# iVLCD register map
Vendor: Texas Instruments
Peripheral module from a debugger description file (folder omap36xx).
Registers are 32-bit, read-write, reset 0x0 unless marked. A register's access mark holds for its fields unless they carry their own. Offsets are as the file gives them; lines under a group give offsets from that group; [hi:lo] are bit positions; {n}, {i} and the like mark numbered series; 'fields as' and 'values as' point back to an identical list; <NAME> marks a mode.

## iVLCD
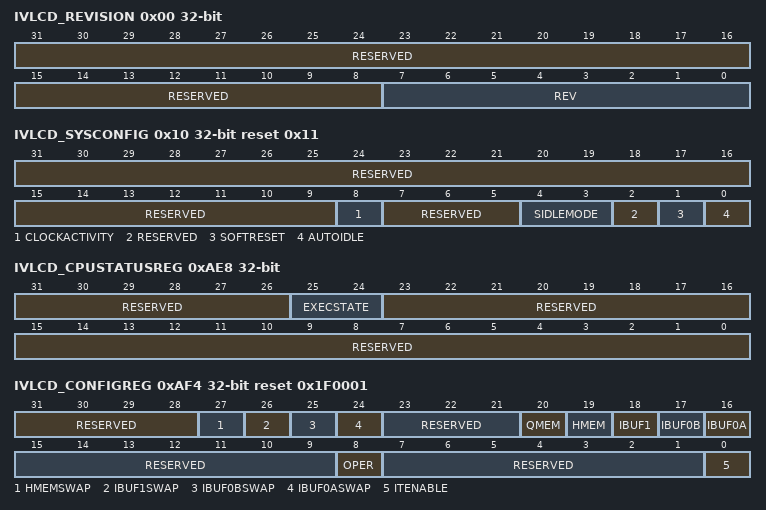
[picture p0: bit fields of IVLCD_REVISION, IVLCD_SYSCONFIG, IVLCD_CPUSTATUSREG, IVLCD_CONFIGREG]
0x00 IVLCD_REVISION ro (reset mask 0xFFFFFF00) — This register contains the iVLCD revision code
  [31:8] RESERVED — Reads return 0
  [7:0] REV — iVLCD Revision[3:0] Minor Revision[7:4] Major Revision
0x10 IVLCD_SYSCONFIG access per field reset 0x11 — This register allows controlling various parameters of the OCP interface
  [31:9] RESERVED rw — Read returns 0.Write has no effect (write a 0 for forward compatibility)
  [8] CLOCKACTIVITY ro — Clock activity during wake up mode period. 0 - OCP clock can be switched-off.
  [7:5] RESERVED rw — Read returns 0.Write has no effect (write a 0 for forward compatibility)
  [4:3] SIDLEMODE ro — Slave interface power management, req/ack control '10' = Smart-idle. Acknowledgement to an idle request is given based on the internal activity of iME
  [2] RESERVED rw — read returns 0.write has no effect (write a 0 for forward compatibility)
  [1] SOFTRESET rw — Software reset. Set this bit to 1 to trigger the iME reset.The bit is automatically reset by the hardware. During reads, it always returns 0.
  [0] AUTOIDLE rw — Internal OCP clock gating strategy: 0: OCP clock is free running 1: Automatic OCP clock-gating strategy is applied based on the OCP interface activity
0x14 IVLCD_SYSSTATUS ro reset 0x1 — The register provides status information about the module, excluding the interrupt information.
  [0] RESETDONE — Internal reset monitoring 0 Internal module reset is on-going 1 Reset completed
0xAE8 IVLCD_CPUSTATUSREG ro — CPU Status Register provides information about the progress of the CPU execution
  [31:26] RESERVED — Read returns 0.
  [25:24] EXECSTATE — Execution States:00 = Initialized,10 = Executing,01 = Halted,11 = Completed.
  [23:0] RESERVED — Read returns 0.
0xAF4 IVLCD_CONFIGREG access per field reset 0x1F0001 — Configuration Register
  [31:28] RESERVED ro — read returns 0.
  [27] HMEMSWAP rw — Enable 2 byte swap for host OCP access to this memory. Bytes 0.1.2.3 are swapped to 1.0.3.2 for both reads and writes.0 - Disabled (Native order)1 - Swapped
  [26] IBUF1SWAP rw — Enable 4 byte swap for host OCP access to this memory. Bytes 0.1.2.3 are swapped to 3.2.1.0 for both reads and writes.0 - Disabled (Native order)1 - Swapped
  [25] IBUF0BSWAP rw — IBUF0B 4 byte swap enable
  [24] IBUF0ASWAP rw — IBUF0A 4 byte swap enable
  [23:21] RESERVED ro — read returns 0.
  [20] QMEM rw — QMEM ownership: 0: QMEM is owned by xVLCD1: QMEM is owned by HOST
  [19] HMEM rw — HMEM ownership: 0: HMEM is owned by xVLCD1: HMEM is owned by HOST
  [18] IBUF1 rw — IBUF1 ownership: 0: IBFU1 is owned by xVLCD1: IBFU1 is owned by HOST
  [17] IBUF0B rw — IBUF0B ownership: 0: IBFU0B is owned by xVLCD1: IBFU0B is owned by HOST
  [16] IBUF0A rw — IBUF0A ownership: 0: IBFU0A is owned by xVLCD1: IBFU0A is owned by HOST
  [15:9] RESERVED ro — read returns 0.
  [8] OPER rw — Operation Type: Used to identify which start to issue to the xVLCD when a START command is set to the iVLCD.0 - VLCD1 - CAVLC
  [7:1] RESERVED ro — Read returns 0.
  [0] ITENABLE rw — Interrupt Enable bit. Controls interrupt regardless of VLCD or CAVLC operation.
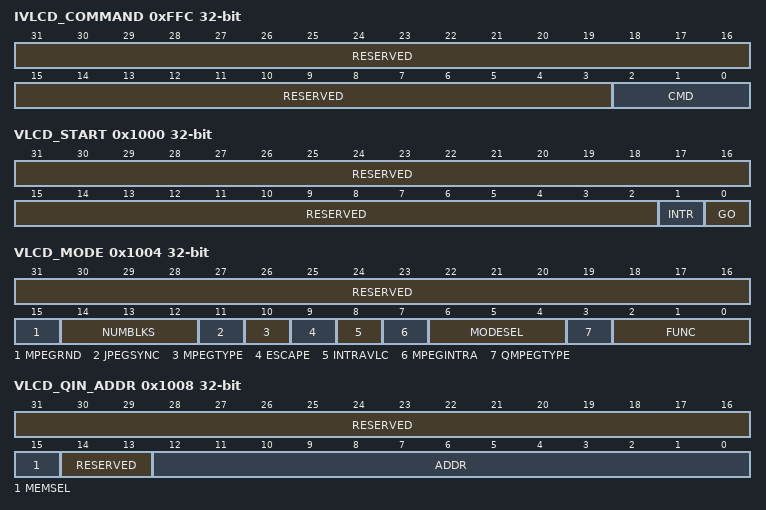
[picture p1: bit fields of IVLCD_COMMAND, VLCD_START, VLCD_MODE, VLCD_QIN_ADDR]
0xFFC IVLCD_COMMAND — Initiate iVLCD operations
  [31:3] RESERVED — Write 0s for future compatibilityRead returns 0
  [2:0] CMD — Triggers iVLCD operations Reads of this register return the last command that was issued to the iVLCD
    1=Start sequence; 2=Stop sequence; 3=Debug enable; 4=Debug disable; 5=Debug Step; 6=Debug Halt
0x1000 VLCD_START — This register starts the VLCD and enables or disables the VLCD interrupt.
  [31:2] RESERVED — Write 0s for future compatibilityRead returns 0
  [1] INTR — Interrupt enable 0: Interrupt is disabled1: Interrupt is enabled
  [0] GO — VLCD startRead0: VLCD idle1: VLCD busy.
0x1004 VLCD_MODE (reset mask 0xFFFFFFF8) — This register sets the VLCD modes.
  [31:16] RESERVED — Write 0s for future compatibilityRead returns 0
  [15] MPEGRND — Round control for the MPEG inverse quantization0: Round off1: Round on
  [14:12] NUMBLKS — Sets the number of blocksRange from 1 '001' to 6 '110'
  [11] JPEGSYNC — Sets the JPEG Sync Insertion0: Off1: On. Inserts 0x00 after 0xFF.
  [10] MPEGTYPE — Sets the MPEG picture coding type0: I, P, B picture1: D picture
  [9] ESCAPE — MPEG4 escape encoding0: Escape3 only1: Escape 1, 2 and 3
  [8] INTRAVLC — MPEG intra VLC format
  [7] MPEGINTRA — Sets the macro block (MB) type0: Non intra macro block1: Intra macro block (JPEG uses only intra MB).
  [6:4] MODESEL — Sets the CODEC type for the VLCD operations000: JPEG001: MPEG1010: MPEG4011: H.263100 - 111: ReservedSee also[5:4] MPGMOD and [2] MP2ENCDEC .
  [3] QMPEGTYPE — Sets the quantization type use for encode and decode.Used in MPEG4.
  [2:0] FUNC — Defines functionality of VLCD
    0=Q; 1=IQ; 2=VLC; 3=VLD; 4=Q + IQ; 5=Q+VLC; 6=Q+IQ+VLC; 7=VLD+IQ
0x1008 VLCD_QIN_ADDR — This register sets the input address for the quantization computation.
  [31:16] RESERVED — Write 0s for future compatibilityRead returns 0
  [15] MEMSEL — Sets the buffer used for the computation0: IMG BUF A/B1: IMG BUF1
  [14:13] RESERVED — Write 0s for future compatibilityRead returns 0
  [12:0] ADDR — Sets the start address for the computation
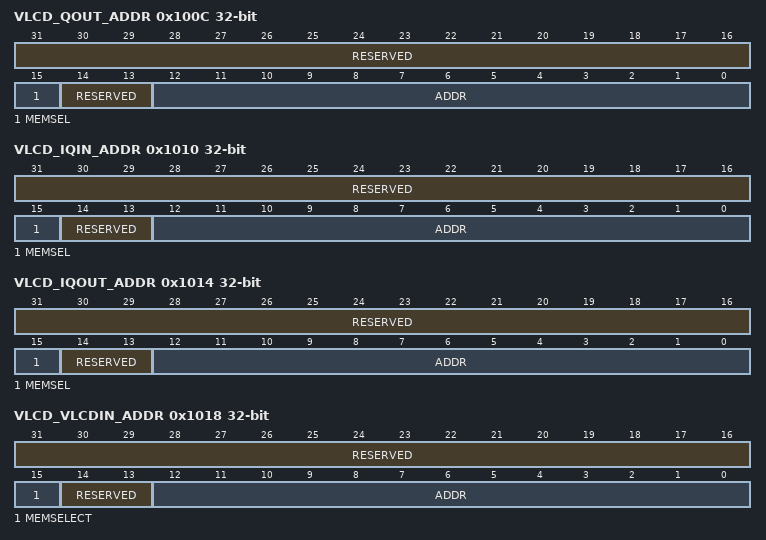
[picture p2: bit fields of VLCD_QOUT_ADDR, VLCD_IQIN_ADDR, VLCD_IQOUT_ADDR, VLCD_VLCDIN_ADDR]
0x100C VLCD_QOUT_ADDR — This register sets the output address for the quantization computation.
  fields as VLCD_QIN_ADDR
0x1010 VLCD_IQIN_ADDR — This register sets the input address for the inverse quantization computation.
  fields as VLCD_QIN_ADDR
0x1014 VLCD_IQOUT_ADDR — This register sets the output address for the inverse quantization output address.
  fields as VLCD_QIN_ADDR
0x1018 VLCD_VLCDIN_ADDR — This register sets the input address for the variable length coder and decoder operations.
  [31:16] RESERVED — Write 0s for future compatibilityRead returns 0
  [15] MEMSELECT — Sets the buffer used for the computation0: IMG BUF A/B1: IMG BUF1
  [14:13] RESERVED — Write 0s for future compatibilityRead returns 0
  [12:0] ADDR — Sets the start address for the computation
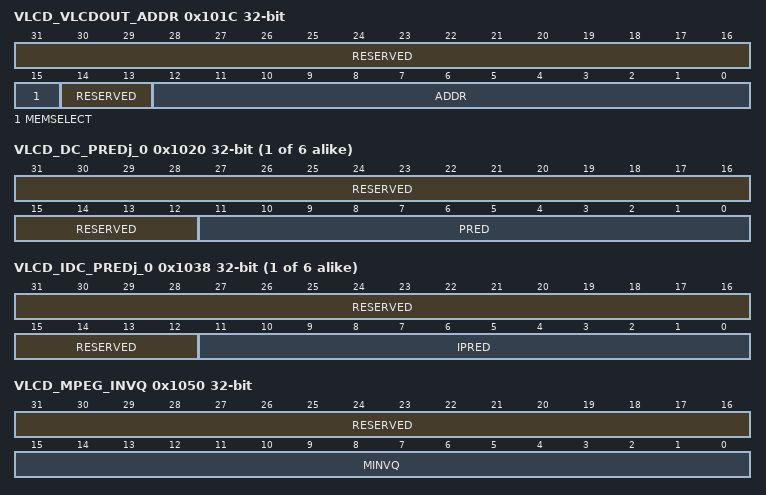
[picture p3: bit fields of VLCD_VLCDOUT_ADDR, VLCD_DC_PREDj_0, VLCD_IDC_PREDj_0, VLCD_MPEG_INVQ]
0x101C VLCD_VLCDOUT_ADDR — This register sets the output address for the variable length coder and decoder operations.
  fields as VLCD_VLCDIN_ADDR
{0x1020+4i} VLCD_DC_PREDj_{i} (i=0..5) — This register sets the initial/final DC predictors for Quantization
  [31:12] RESERVED — Write 0s for future compatibilityRead returns 0
  [11:0] PRED — Initial/ final DC predictor value
{0x1038+4i} VLCD_IDC_PREDj_{i} (i=0..5) — This register sets the initial/final DC predictors for Inverse Quantization
  [31:12] RESERVED — Write 0s for future compatibilityRead returns 0
  [11:0] IPRED — Initial/ final DC predictor value
0x1050 VLCD_MPEG_INVQ — This register sets the inverse quantization value used in MPEG.
  [31:16] RESERVED — Write 0s for future compatibilityRead returns 0
  [15:0] MINVQ — 2^15/quant_scale
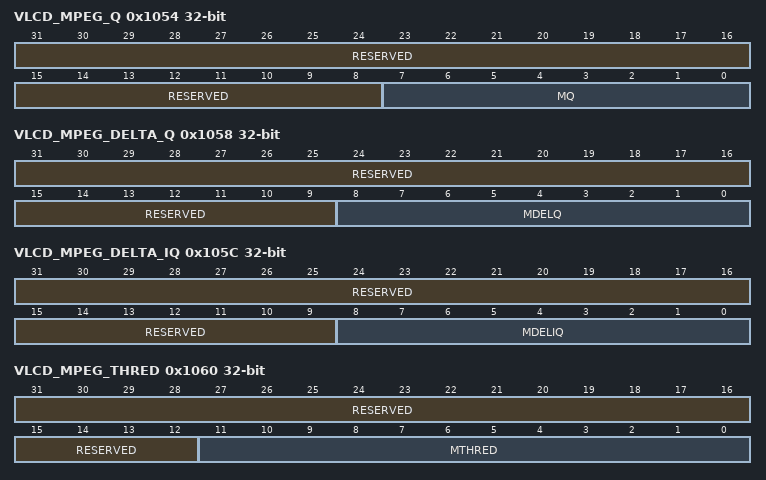
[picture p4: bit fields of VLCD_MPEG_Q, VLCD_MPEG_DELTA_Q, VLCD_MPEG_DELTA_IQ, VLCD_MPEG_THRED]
0x1054 VLCD_MPEG_Q — This register sets the quantization value used in MPEG.
  [31:8] RESERVED — Write 0s for future compatibilityRead returns 0
  [7:0] MQ — quant_scale
0x1058 VLCD_MPEG_DELTA_Q — This register sets the delta value used in MPEG quantization
  [31:9] RESERVED — Write 0s for future compatibilityRead returns 0
  [8:0] MDELQ — Number of delta values2's complement
0x105C VLCD_MPEG_DELTA_IQ — This register sets the delta value used in MPEG inverse quantization
  [31:9] RESERVED — Write 0s for future compatibilityRead returns 0
  [8:0] MDELIQ — Number of delta values2's complement
0x1060 VLCD_MPEG_THRED — This register sets the number of threads used in MPEG quantization
  [31:12] RESERVED — Write 0s for future compatibilityRead returns 0
  [11:0] MTHRED — Number of threads
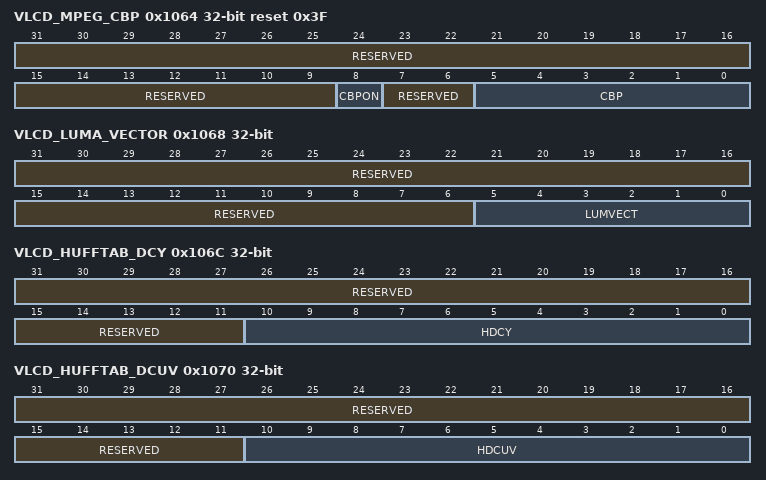
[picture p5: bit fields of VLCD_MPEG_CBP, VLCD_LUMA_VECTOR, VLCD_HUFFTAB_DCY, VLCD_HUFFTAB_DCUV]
0x1064 VLCD_MPEG_CBP reset 0x3F — This register sets the coded block pattern (CBP) configuration.
  [31:9] RESERVED — Write 0s for future compatibilityRead returns 0
  [8] CBPON — CBP detect enable0: CBP detect off (JPEG)1: CBP detect on
  [7:6] RESERVED — Write 0s for future compatibilityRead returns 0
  [5:0] CBP — CBP indicating at least one nonzero in a block1XXXXX: CBP of the 1st blockX1XXXX: CBP of the 2nd blockXX1XXX: CBP of the 3rd blockXXX1XX: CBP of the 4th blockXXXX1X: CBP of the 5th blockXXXXX1: CBP of the 6th block
0x1068 VLCD_LUMA_VECTOR — This register sets the luma bit vector
  [31:6] RESERVED — Write 0s for future compatibilityRead returns 0
  [5:0] LUMVECT — Luma bit vector1XXXXXLuma bit of the 1st blockX1XXXXLuma bit of the 2nd blockXX1XXXLuma bit of the 3rd blockXXX1XXLuma bit of the 4th blockXXXX1XLuma bit of the 5th blockXXXXX1Luma bit of the 6th block
0x106C VLCD_HUFFTAB_DCY — This register sets the base address for Huffman DC tables.
  [31:11] RESERVED — Write 0s for future compatibilityRead returns 0
  [10:0] HDCY — Start address.Must be align on a 32-bit boundary
0x1070 VLCD_HUFFTAB_DCUV — This register sets the base address for Huffman DC tables.
  [31:11] RESERVED — Write 0s for future compatibilityRead returns 0
  [10:0] HDCUV — Start address.Must be align on a 32-bit boundary
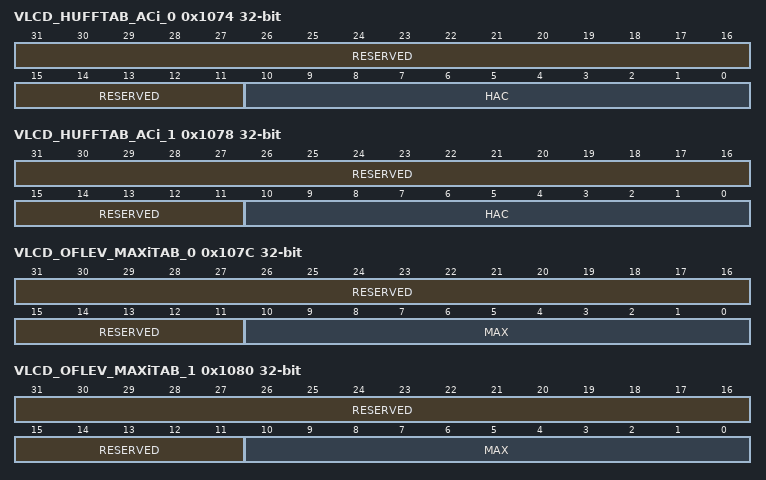
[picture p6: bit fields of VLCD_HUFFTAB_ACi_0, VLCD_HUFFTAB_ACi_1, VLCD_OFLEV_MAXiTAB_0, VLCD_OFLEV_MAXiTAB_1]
0x1074 VLCD_HUFFTAB_ACi_0 — This register sets the base address for Huffman AC tables.
  [31:11] RESERVED — Write 0s for future compatibilityRead returns 0
  [10:0] HAC — Start address.Must be align on a 32-bit boundary
0x1078 VLCD_HUFFTAB_ACi_1 — This register sets the base address for Huffman AC tables.
  fields as VLCD_HUFFTAB_ACi_0
0x107C VLCD_OFLEV_MAXiTAB_0 — This register sets the base address for MPEG max level tables
  [31:11] RESERVED — Write 0s for future compatibilityRead returns 0
  [10:0] MAX — Start address.Must be align on a 32-bit boundary
0x1080 VLCD_OFLEV_MAXiTAB_1 — This register sets the base address for MPEG max level tables
  fields as VLCD_OFLEV_MAXiTAB_0
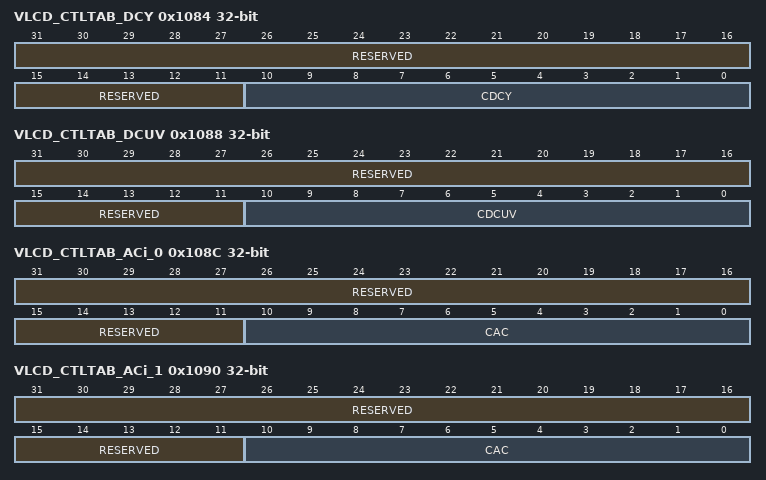
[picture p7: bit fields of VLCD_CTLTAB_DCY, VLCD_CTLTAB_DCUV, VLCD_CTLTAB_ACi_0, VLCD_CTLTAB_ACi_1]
0x1084 VLCD_CTLTAB_DCY — This register sets the base address of the control-table DC Y LUT used by the UVLD.
  [31:11] RESERVED — Write 0s for future compatibilityRead returns 0
  [10:0] CDCY — Start address.Must be align on a 32-bit boundary
0x1088 VLCD_CTLTAB_DCUV — This register sets the base address of the control-table DC UV LUT used by the UVLD.
  [31:11] RESERVED — Write 0s for future compatibilityRead returns 0
  [10:0] CDCUV — Start address.Must be align on a 32-bit boundary
0x108C VLCD_CTLTAB_ACi_0 — This register sets the base address of the control-table ACi LUT used by the UVLD.
  [31:11] RESERVED — Write 0s for future compatibilityRead returns 0
  [10:0] CAC — Start address.Must be align on a 32-bit boundary
0x1090 VLCD_CTLTAB_ACi_1 — This register sets the base address of the control-table ACi LUT used by the UVLD.
  fields as VLCD_CTLTAB_ACi_0
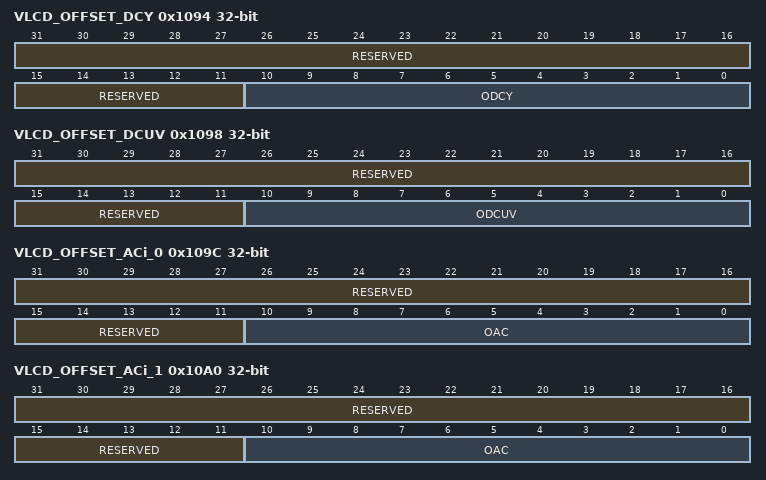
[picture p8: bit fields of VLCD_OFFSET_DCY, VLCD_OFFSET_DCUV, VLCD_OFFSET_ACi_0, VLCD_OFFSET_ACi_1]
0x1094 VLCD_OFFSET_DCY — This register sets the offset value used to address the symbol-table DC Y LUT.
  [31:11] RESERVED — Write 0s for future compatibilityRead returns 0
  [10:0] ODCY — Offset value
0x1098 VLCD_OFFSET_DCUV — This register sets the offset value used to address the symbol-table DC UV LUT.
  [31:11] RESERVED — Write 0s for future compatibilityRead returns 0
  [10:0] ODCUV — Offset value
0x109C VLCD_OFFSET_ACi_0 — This register sets the offset value used to address the symbol-table ACi LUT.
  [31:11] RESERVED — Write 0s for future compatibilityRead returns 0
  [10:0] OAC — Offset value
0x10A0 VLCD_OFFSET_ACi_1 — This register sets the offset value used to address the symbol-table ACi LUT.
  fields as VLCD_OFFSET_ACi_0
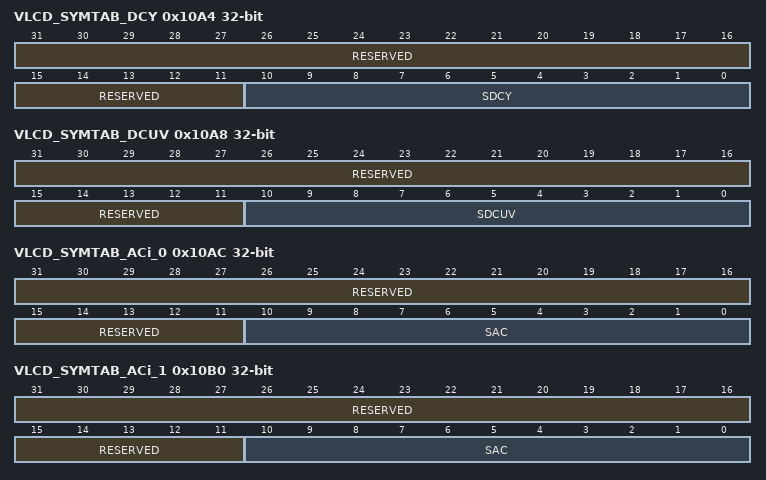
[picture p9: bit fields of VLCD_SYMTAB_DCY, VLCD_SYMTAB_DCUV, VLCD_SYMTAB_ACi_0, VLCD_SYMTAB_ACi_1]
0x10A4 VLCD_SYMTAB_DCY — This register sets the base address of the symbol-table DC Y LUT.
  [31:11] RESERVED — Write 0s for future compatibilityRead returns 0
  [10:0] SDCY — Start address.Must be align on a 32-bit boundary
0x10A8 VLCD_SYMTAB_DCUV — This register sets the base address of the symbol-table DC UV LUT.
  [31:11] RESERVED — Write 0s for future compatibilityRead returns 0
  [10:0] SDCUV — Start address.Must be align on a 32-bit boundary
0x10AC VLCD_SYMTAB_ACi_0 — This register sets the base address of the symbol-table ACi UV LUT.
  [31:11] RESERVED — Write 0s for future compatibilityRead returns 0
  [10:0] SAC — Start address.Must be align on a 32-bit boundary
0x10B0 VLCD_SYMTAB_ACi_1 — This register sets the base address of the symbol-table ACi UV LUT.
  fields as VLCD_SYMTAB_ACi_0
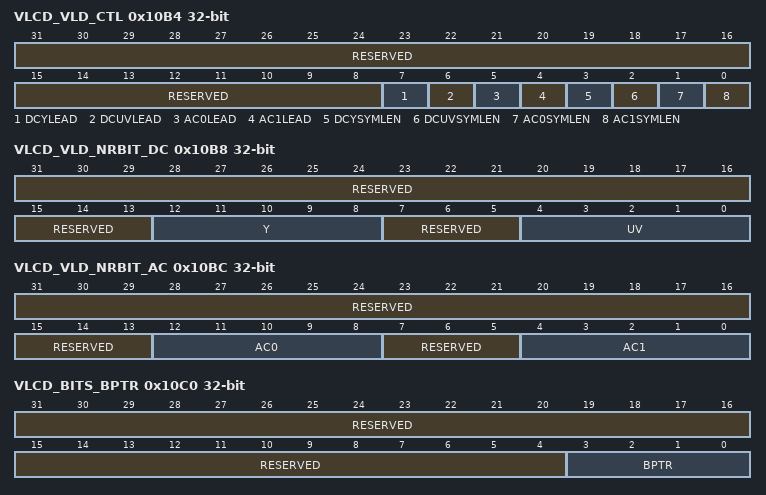
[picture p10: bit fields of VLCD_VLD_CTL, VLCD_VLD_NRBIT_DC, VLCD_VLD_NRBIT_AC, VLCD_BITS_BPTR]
0x10B4 VLCD_VLD_CTL (reset mask 0xFFFFFFFC) — This register controls the VLD operations
  [31:8] RESERVED — Write 0s for future compatibilityRead returns 0
  [7] DCYLEAD — This bit signifies that the UVLD is expecting a 1 leadingHuffman table for the DC Y table.
  [6] DCUVLEAD — This bit signifies that the UVLD is expecting a 1 leadingHuffman table for the DC UV table.
  [5] AC0LEAD — This bit signifies that the UVLD is expecting a 1 leadingHuffman table for the AC0 table.
  [4] AC1LEAD — This bit signifies that the UVLD is expecting a 1 leadingHuffman table for the AC1 table.
  [3] DCYSYMLEN — Decoded symbol bit length in DC Y table0: 12-bit symbol1: 11-bit symbol
  [2] DCUVSYMLEN — Decoded symbol bit length in DC UV table0: 12-bit symbol1: 11-bit symbol
  [1] AC0SYMLEN — Decoded symbol bit length in AC0 table0: 12-bit symbol1: 11-bit symbol
  [0] AC1SYMLEN — Decoded symbol bit length in AC1 table0: 12-bit symbol1: 11-bit symbol
0x10B8 VLCD_VLD_NRBIT_DC — This register controls the UVLD operations for the DC terms
  [31:13] RESERVED — Write 0s for future compatibilityRead returns 0
  [12:8] Y — Number of bits to test for the DC Y term as input to UVLD
  [7:5] RESERVED — Write 0s for future compatibilityRead returns 0
  [4:0] UV — Number of bits to test for the DC UV term as input to UVLD
0x10BC VLCD_VLD_NRBIT_AC — This register controls the UVLD operations for the AC terms
  [31:13] RESERVED — Write 0s for future compatibilityRead returns 0
  [12:8] AC0 — Number of bits to test for the AC0 term as input to UVLD
  [7:5] RESERVED — Write 0s for future compatibilityRead returns 0
  [4:0] AC1 — Number of bits to test for the AC1 term as input to UVLD
0x10C0 VLCD_BITS_BPTR — Number of valid bit pointer
  [31:4] RESERVED — Write 0s for future compatibilityRead returns 0
  [3:0] BPTR — Number of valid bits in the 16-bit word pointed byVLCD_OUT.StartAddr or VLCD_IN.StartAddr
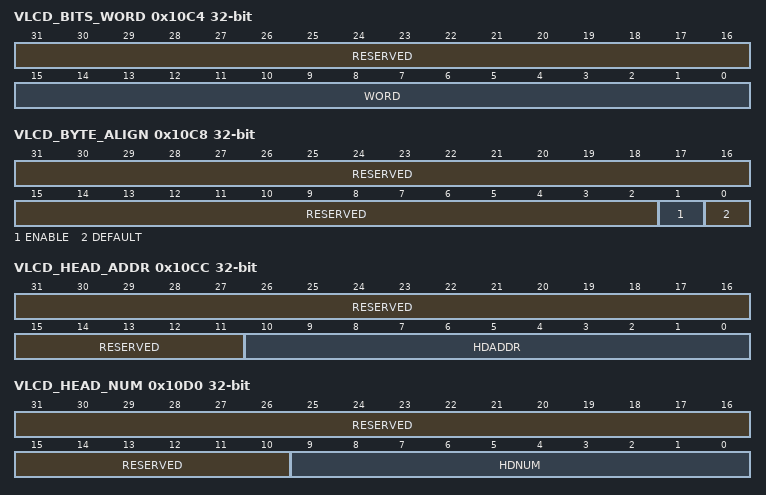
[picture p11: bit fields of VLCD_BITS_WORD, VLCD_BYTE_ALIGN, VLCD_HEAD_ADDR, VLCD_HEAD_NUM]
0x10C4 VLCD_BITS_WORD — Bit stream
  [31:16] RESERVED — Write 0s for future compatibilityRead returns 0
  [15:0] WORD — Last bitstream
0x10C8 VLCD_BYTE_ALIGN — VLC byte align
  [31:2] RESERVED — Write 0s for future compatibilityRead returns 0
  [1] ENABLE — VLC: When set to '1' , it enable byte align in current processing macro blockVLD: When set to '1', it means current processing bitstream is byte aligned.
  [0] DEFAULT — VLC: When byte-align is selected (ENABLE bit set to '1'), last byte is filled with this bit.VLD: No meaning
0x10CC VLCD_HEAD_ADDR — This register sets the base address for header data to be inserted.
  [31:11] RESERVED — Write 0s for future compatibilityRead returns 0
  [10:0] HDADDR — Base address for header data to be insertedMust be align on a 32-bit boundary
0x10D0 VLCD_HEAD_NUM — This register sets the number of header data to be inserted.
  [31:10] RESERVED — Write 0s for future compatibilityRead returns 0
  [9:0] HDNUM — Number of header data to be inserted1 to 1023
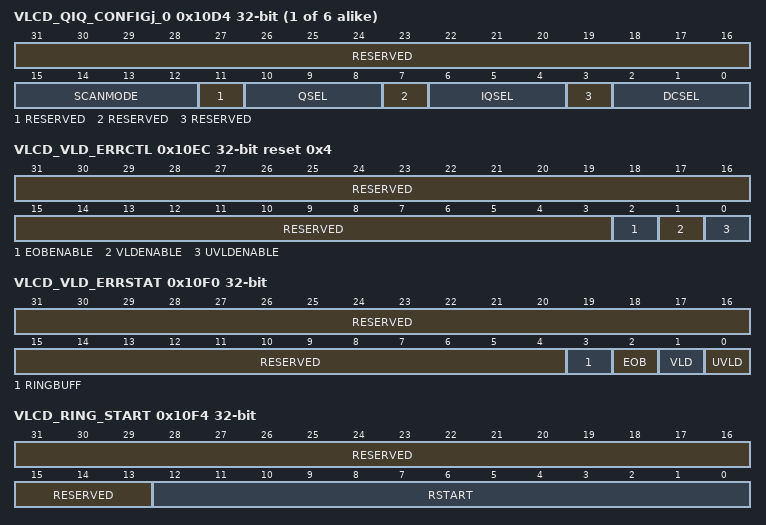
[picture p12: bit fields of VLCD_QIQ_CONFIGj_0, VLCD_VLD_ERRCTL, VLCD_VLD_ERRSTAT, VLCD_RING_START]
{0x10D4+4i} VLCD_QIQ_CONFIGj_{i} (i=0..5) — This register sets the Q/IQ config for block i
  [31:16] RESERVED — Write 0s for future compatibilityRead returns 0
  [15:12] SCANMODE — Sets the scan mode (VLC/VLD)00 Linear scan01 Zig-Zag scan10 Alternate vertical scan11 Alternate horizontal scan
  [11] RESERVED — Write 0s for future compatibilityRead returns 0
  [10:8] QSEL — Quantization matrix selector1 of 8 banks
  [7] RESERVED — Write 0s for future compatibilityRead returns 0
  [6:4] IQSEL — Inverse quantization matrix selector 1 of 8 banks
  [3] RESERVED — Write 0s for future compatibilityRead returns 0
  [2:0] DCSEL — DC predictor selector1 of 6 banks
0x10EC VLCD_VLD_ERRCTL reset 0x4 — This register control the VLCD error enables.
  [31:3] RESERVED — Write 0s for future compatibilityRead returns 0
  [2] EOBENABLE — EOB error control0: Off1: On
  [1] VLDENABLE — VLD error control. When JPEG or MPEG1/2 mode, thisbit should be set to 0 (off).0: Off1: On
  [0] UVLDENABLE — UVLD error control0: Off1: On
0x10F0 VLCD_VLD_ERRSTAT ro — This register reports VLCD errors
  [31:4] RESERVED — Write 0s for future compatibilityRead returns 0
  [3] RINGBUFF — Ring buffer overflow status
  [2] EOB — EOB error
  [1] VLD — VLD errorJPEG: Goes '1' when found FDX code at the end of MBH.263, MPEG4: Goes '1' when found an FLC error
  [0] UVLD — UVLD error
0x10F4 VLCD_RING_START — This register sets the ring buffer start address.
  [31:13] RESERVED — Write 0s for future compatibilityRead returns 0
  [12:0] RSTART — Ring buffer start address
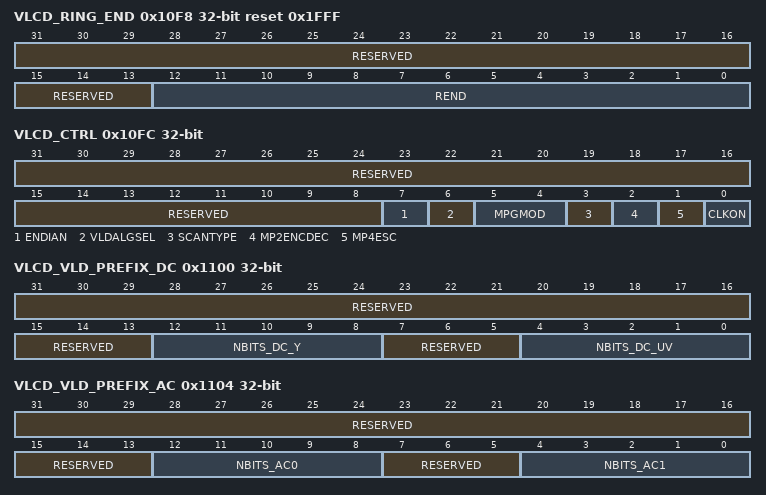
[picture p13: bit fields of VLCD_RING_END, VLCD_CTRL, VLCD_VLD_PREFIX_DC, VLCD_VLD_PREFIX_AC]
0x10F8 VLCD_RING_END reset 0x1FFF — This register sets the ring buffer end address.
  [31:13] RESERVED — Write 0s for future compatibilityRead returns 0
  [12:0] REND — Ring buffer end addressVLC:When output pointer reaches the end address, pointer starts at start pointer automatically.VLD:When input pointer reaches the end address, pointer starts at start pointer automatically.
0x10FC VLCD_CTRL — VLCD control register
  [31:8] RESERVED — Write 0s for future compatibilityRead returns 0
  [7] ENDIAN — Endianism control0: Big endian1: Little endian
  [6] VLDALGSEL — VLD algorithm selection0: Same as DM270 or before (all except MPEG4 RVLC, H.264, and WMV9)1: New algorithm for DM275 or after (must for MPEG4 RVLC, can also be used for others except H.264 and WMV9)
  [5:4] MPGMOD — Additional MPEG mode0: MPEG4 normal1: MPEG4 data partitioning2: MPEG4 RVLC3: WMV9 (decode only) Field active when VLCD_MODE(5:4) = MPEG4
  [3] SCANTYPE — SCAN mode0: SCAN type is selected by VLCD_MODE(9:8)1: SCAN type is selected by Q/IQ_CONFIG1 to Q/IQ_CONFIG5
  [2] MP2ENCDEC — MPEG2 encode/decode0: MPEG1 VLCD_MODE(5:4) = MPEG11: MPEG2 VLCD_MODE(5:4) = MPEG1
  [1] MP4ESC — MPEG4 escape encoding0: Escape3 only(DSC25)1: Escape1,2 and 3
  [0] CLKON — Dynamic clock on/off control0: On 1: Off
0x1100 VLCD_VLD_PREFIX_DC — This register sets the ring buffer end address.
  [31:13] RESERVED — Write 0s for future compatibilityRead returns 0
  [12:8] NBITS_DC_Y — Sets the number of prefix bits of control table for theDCY term as input to the UVLD.
  [7:5] RESERVED — Write 0s for future compatibilityRead returns 0
  [4:0] NBITS_DC_UV — Sets the number of prefix bits of control table for theDCUV term as input to the UVLD.
0x1104 VLCD_VLD_PREFIX_AC — This register sets the ring buffer end address.
  [31:13] RESERVED — Write 0s for future compatibilityRead returns 0
  [12:8] NBITS_AC0 — Sets the number of prefix bits of control table for theAC0 term as input to the UVLD.
  [7:5] RESERVED — Write 0s for future compatibilityRead returns 0
  [4:0] NBITS_AC1 — Sets the number of prefix bits of control table for theAC1 term as input to the UVLD.
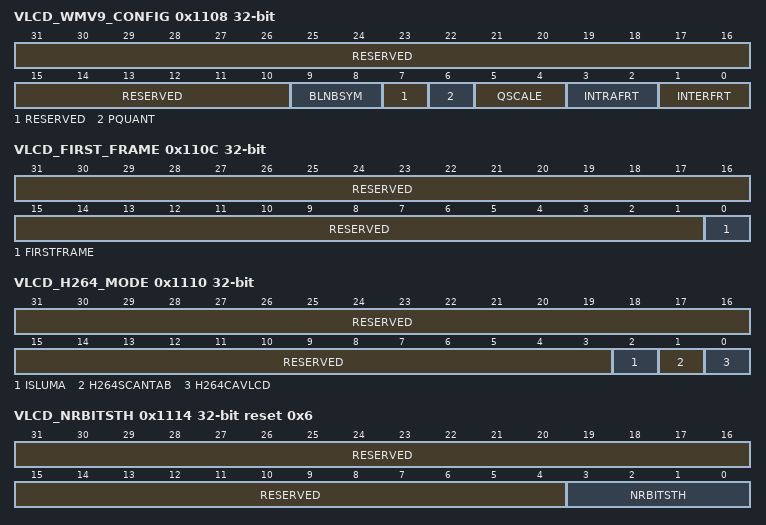
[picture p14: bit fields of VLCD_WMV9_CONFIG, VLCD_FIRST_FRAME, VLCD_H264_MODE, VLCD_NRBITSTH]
0x1108 VLCD_WMV9_CONFIG — This register controls the WMV9 parameters
  [31:10] RESERVED — Write 0s for future compatibilityRead returns 0
  [9:8] BLNBSYM — Specifies the number of symbols in a block
    0=64; 1=32; 2=160x3: Reserved
  [7] RESERVED — Write 0s for future compatibility. Read returns 0.
  [6] PQUANT — Setting this bit to '1' specify: PQUANT&gt;=8, I-Frame
  [5:4] QSCALE — Quantization Scale
  [3:2] INTRAFRT — Intra frame rate type
    0=low motion; 1=high motion; 2=mid rate; 3=high rate
  [1:0] INTERFRT — Inter frame rate type
    0=low motion; 1=high motion; 2=mid rate; 3=high rate
0x110C VLCD_FIRST_FRAME — This register specifies the first case of escape mode 3 in a frame
  [31:1] RESERVED — Write 0s for future compatibilityRead returns 0
  [0] FIRSTFRAME — Setting '1' specifies the first case of escape mode 3 in a frame, this register is cleared when found a ESCAPE3(WMV9)
0x1110 VLCD_H264_MODE — This register configure H264 mode of operation
  [31:3] RESERVED — Write 0s for future compatibilityRead returns 0
  [2] ISLUMA — 4×4, 4x8 subblock to 8x8 block conversionThis register is for H.264 and WMV9 .
    0=linear order; 1=stores the data as 8x8 block image
  [1] H264SCANTAB — Setting 1 selects the H.264 SCAN table(IQ mode)
  [0] H264CAVLCD — Setting 1 enable the H.264 CAVLC decoding
0x1114 VLCD_NRBITSTH reset 0x6 — This register sets the threshold level of 'nrbits' (number of bits) in WMV9.
  [31:4] RESERVED — Write 0s for future compatibilityRead returns 0
  [3:0] NRBITSTH — Threshold level of 'nrbits' (number of bits) in WMV9 decoding.When the 'nrbits' gotten from the Huffman table is greater than this threshold value, UVLD error happens. Current VLD algorithm defines the maximum 'nrbits' is 6. No need to modify the default value.
0x1140 CAVLC_GO_REG — CAVLC enable register
  [31:1] RESERVED — Write 0s for future compatibilityRead returns 0
  [0] CAVLC_GO — Setting this bit will start CAVLC module. This bit is high while CAVLC module is running and cleared automatically after the completion of the job.
0x1144 CAVLC_MBTYPE — This register controls the macro-block type
  [31:9] RESERVED — Write 0s for future compatibilityRead returns 0
  [8] INTRA1616 — Set high when intra16x16 macroblock
  [7:6] RESERVED — Write 0s for future compatibilityRead returns 0
  [5:0] CODBLKPAT — Set coded block pattern as the H.264 standard describes
0x1148 CAVLC_RBTOP — This register sets the Ring Buffer Top Pointer
  [31:13] RESERVED — Write 0s for future compatibilityRead returns 0
  [12:0] RBTOP — Set Ring Buffer Top pointer in Image Buffer. The value must be even.If IBUF0 is selected in CAVLC_IBUFSEL, bit 12 select if IBUF0_A (0) or IBUF0_B (1) is used.
0x114C CAVLC_RBEND — This register sets the Ring Buffer End Pointer
  [31:13] RESERVED — Write 0s for future compatibilityRead returns 0
  [12:0] RBEND — Set Ring Buffer End pointer in Image Buffer. The value must be even. RBEND+1 will be the final word address of Ring Buffer. CAVLC_RBEND
0x1150 CAVLC_BUFPTR — This register sets the bitstream start pointer
  [31:13] RESERVED — Write 0s for future compatibilityRead returns 0
  [12:0] BUFPTR — Set a pointer inside Ring Buffer from which bitstream will be written. After the completion, the final pointer is shown. Must be even number. If IBUF0 is selected in CAVLC_IBUFSEL, bit 12 select if IBUF0_A (0) or IBUF0_B (1) is used.
0x1154 CAVLC_BITPTR — This register sets the number of valid MSBs in stream word registers.
  [31:5] RESERVED — Write 0s for future compatibilityRead returns 0
  [4:0] BITPTR — Set the number of valid MSBs in stream word registers. The bitstream to be generated follows the valid bits. It shows the number of valid MSBs in stream word registers after completion of the job.
0x1158 CAVLC_STRMWDU — Upper half of 32-bit Stream Word Register
  [31:16] RESERVED — Write 0s for future compatibilityRead returns 0
  [15:0] STRMWDU — Upper half of 32-bit Stream Word Register. Write bits from MSB so that bitstream to be generated follows them. After the completion of the job, remaining bits, which is less than 32 and not written to Image Buffer, is shown.
0x115C CAVLC_STRMWDL — Lower half of 32-bit Stream Word Register
  [31:16] RESERVED — Write 0s for future compatibilityRead returns 0
  [15:0] STRMWDL — Lower half of 32-bit Stream Word Register. Write bits from MSB so that bitstream to be generated follows them. After the completion of the job, remaining bits, which is less than 32 and not written to Image Buffer, is shown.
0x1160 CAVLC_HDPTR — This register sets Huffman memory read pointer
  [31:12] RESERVED — Write 0s for future compatibilityRead returns 0
  [11:0] HDPTR — Set a pointer in Huffman memory from which CAVLC will read pairs of an MB header symbol and its length, and pack the symbols into bitstream. Must be even number.
0x1164 CAVLC_HDCOUNT — This register sets the number of MB header pairs to be inserted to bitstream
  [31:10] RESERVED — Write 0s for future compatibilityRead returns 0
  [9:0] HDCOUNT — Set the number of MB header pairs to be inserted to bitstream. The number is 0 to 1023.
0x1168 CAVLC_NAPTR — This register sets Huffman memory write nA pointer
  [31:12] RESERVED — Write 0s for future compatibilityRead returns 0
  [11:0] NAPTR — Set a pointer in Huffman memory from which nAs are stored. Must be even. After the completion of the job, the number of coefficients of 4x4-blocks in the most right column will be stored from this pointer.
0x116C CAVLC_NBPTR — This register sets Huffman memory write nB pointer
  [31:12] RESERVED — Write 0s for future compatibilityRead returns 0
  [11:0] NBPTR — Set a pointer in Huffman memory from which nBs are stored. Must be even. After the completion of the job, the number of coefficients of 4x4-blocks in the lowest row will be stored from this pointer.
0x1170 CAVLC_COEFFPTR — This register sets coefficients memory pointer
  [31:13] RESERVED — Write 0s for future compatibilityRead returns 0
  [12:0] COEFFPTR — Set a pointer in Image Buffer from which residual coefficients are stored. Must be even.If IBUF0 is selected in CAVLC_IBUFSEL, bit 12 select if IBUF0_A (0) or IBUF0_B (1) is used.
0x1174 CAVLC_IBUFSEL — This register controls selects IBUF0 or IBUF1 and controls byte swapping
  [31:5] RESERVED — Write 0s for future compatibilityRead returns 0
  [4] BYTESWP — Stream byte swap control bit.0: Normal1: Swap the two bytes in each 16-bit word.
  [3:2] RESERVED — Write 0s for future compatibilityRead returns 0
  [1] INPRTSEL — Select input port,0: ibuf0 port,1: ibuf1 port.Input port and output port are allowed to be assigned to the same port.
  [0] OUTPRTSEL — Select output port,0: ibuf0 port,1: ibuf1 port.Input port and output port are allowed to be assigned to the same port.
0x1178 CAVLC_NUMTTL ro — number of bits generated
  [31:16] RESERVED — Read returns 0
  [15:0] NUMTTL — Showing how many bits are generated in total. Automatically cleared when the job starts.
0x117C CAVLC_NUMHD ro
  [31:16] RESERVED — Read returns 0
  [15:0] NUMHD — Showing how many bits are generated from MB headers. Automatically cleared when the job starts.
0x1180 CAVLC_NUMRESI ro — Showing how many bits are generated from residual coefficients. Automatically cleared when the job starts.
  [31:16] RESERVED — Read returns 0
  [15:0] NUMRESI — Showing how many bits are generated from MB headers. Automatically cleared when the job starts.
